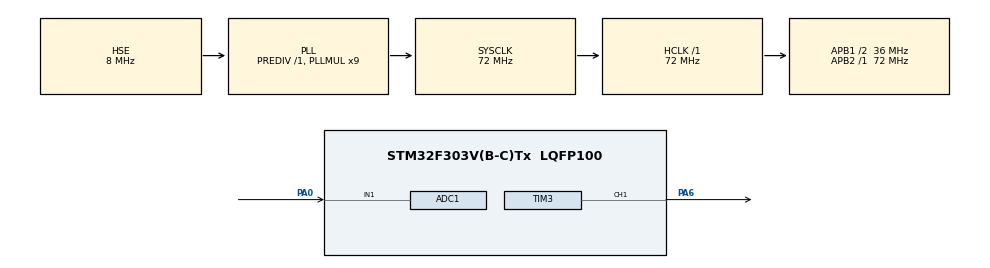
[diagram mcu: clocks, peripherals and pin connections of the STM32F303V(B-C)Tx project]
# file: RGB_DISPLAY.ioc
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ADC1.Channel-0\#ChannelRegularConversion=ADC_CHANNEL_1
ADC1.ContinuousConvMode=DISABLE
ADC1.DMAContinuousRequests=ENABLE
ADC1.EOCSelection=ADC_EOC_SINGLE_CONV
ADC1.EnableInjectedConversion=DISABLE
ADC1.ExternalTrigConv=ADC_EXTERNALTRIGCONV_T6_TRGO
ADC1.NbrOfConversionFlag=1
ADC1.Offset-0\#ChannelRegularConversion=0
ADC1.OffsetNumber-0\#ChannelRegularConversion=ADC_OFFSET_NONE
ADC1.Rank-0\#ChannelRegularConversion=1
ADC1.SamplingTime-0\#ChannelRegularConversion=ADC_SAMPLETIME_1CYCLE_5
ADC1.master=1
Dma.ADC1.1.Direction=DMA_PERIPH_TO_MEMORY
Dma.ADC1.1.Instance=DMA1_Channel1
Dma.ADC1.1.MemDataAlignment=DMA_MDATAALIGN_HALFWORD
Dma.ADC1.1.MemInc=DMA_MINC_ENABLE
Dma.ADC1.1.Mode=DMA_CIRCULAR
Dma.ADC1.1.PeriphDataAlignment=DMA_PDATAALIGN_HALFWORD
Dma.ADC1.1.PeriphInc=DMA_PINC_DISABLE
Dma.ADC1.1.Priority=DMA_PRIORITY_HIGH
Dma.Request0=TIM3_CH4/UP
Dma.Request1=ADC1
Dma.TIM3_CH4/UP.0.Direction=DMA_MEMORY_TO_PERIPH
Dma.TIM3_CH4/UP.0.Instance=DMA1_Channel3
Dma.TIM3_CH4/UP.0.MemDataAlignment=DMA_MDATAALIGN_HALFWORD
Dma.TIM3_CH4/UP.0.MemInc=DMA_MINC_ENABLE
Dma.TIM3_CH4/UP.0.Mode=DMA_CIRCULAR
Dma.TIM3_CH4/UP.0.PeriphDataAlignment=DMA_PDATAALIGN_HALFWORD
Dma.TIM3_CH4/UP.0.PeriphInc=DMA_PINC_DISABLE
Dma.TIM3_CH4/UP.0.Priority=DMA_PRIORITY_VERY_HIGH
Mcu.Family=STM32F3
Mcu.Name=STM32F303V(B-C)Tx
Mcu.Package=LQFP100
NVIC.DMA1_Channel1_IRQn=true\:0\:0\:false\:false\:true\:false
NVIC.DMA1_Channel3_IRQn=true\:0\:0\:false\:false\:true\:false
NVIC.PriorityGroup=NVIC_PRIORITYGROUP_4
NVIC.TIM7_IRQn=true\:0\:0\:false\:false\:true\:true
PA0.Mode=IN1-Single-Ended
PA0.Signal=ADC1_IN1
PA13.Mode=Serial_Wire
PA13.Signal=SYS_JTMS-SWDIO
PA14.Mode=Serial_Wire
PA14.Signal=SYS_JTCK-SWCLK
PA6.GPIO_Speed=GPIO_SPEED_FREQ_LOW
PA6.Signal=S_TIM3_CH1
PC14-OSC32_IN.Mode=LSE-External-Oscillator
PC14-OSC32_IN.Signal=RCC_OSC32_IN
PC15-OSC32_OUT.Mode=LSE-External-Oscillator
PC15-OSC32_OUT.Signal=RCC_OSC32_OUT
PF0-OSC_IN.Mode=HSE-External-Oscillator
PF0-OSC_IN.Signal=RCC_OSC_IN
PF1-OSC_OUT.Mode=HSE-External-Oscillator
PF1-OSC_OUT.Signal=RCC_OSC_OUT
ProjectManager.HeapSize=0x200
ProjectManager.StackSize=0x400
ProjectManager.TargetToolchain=Makefile
RCC.AHBFreq_Value=72000000
RCC.APB1CLKDivider=RCC_HCLK_DIV2
RCC.APB1Freq_Value=36000000
RCC.APB1TimFreq_Value=72000000
RCC.APB2Freq_Value=72000000
RCC.APB2TimFreq_Value=72000000
RCC.CortexFreq_Value=72000000
RCC.HCLKFreq_Value=72000000
RCC.HSE_VALUE=8000000
RCC.HSI_VALUE=8000000
RCC.PLLMUL=RCC_PLL_MUL9
RCC.PLLSourceVirtual=RCC_PLLSOURCE_HSE
RCC.SYSCLKFreq_VALUE=72000000
RCC.SYSCLKSourceVirtual=RCC_SYSCLKSOURCE_PLLCLK
RCC.USBFreq_Value=72000000
SH.S_TIM3_CH1.0=TIM3_CH1,PWM Generation1 CH1
TIM3.AutoReloadPreload=TIM_AUTORELOAD_PRELOAD_ENABLE
TIM3.Channel-PWM\ Generation1\ CH1=TIM_CHANNEL_1
TIM3.OCMode_PWM-PWM\ Generation1\ CH1=TIM_OCMODE_PWM1
TIM3.Period=12
TIM3.Prescaler=6
TIM3.Pulse-PWM\ Generation1\ CH1=0
TIM3.TIM_MasterOutputTrigger=TIM_TRGO_UPDATE
TIM6.AutoReloadPreload=TIM_AUTORELOAD_PRELOAD_ENABLE
TIM6.Period=49
TIM6.Prescaler=72
TIM6.TIM_MasterOutputTrigger=TIM_TRGO_UPDATE
TIM7.AutoReloadPreload=TIM_AUTORELOAD_PRELOAD_ENABLE
TIM7.Period=9999
TIM7.Prescaler=72
TIM7.TIM_MasterOutputTrigger=TIM_TRGO_RESET
VP_TIM3_VS_ClockSourceINT.Mode=Internal
VP_TIM6_VS_ClockSourceINT.Mode=Enable_Timer
VP_TIM7_VS_ClockSourceINT.Mode=Enable_Timer
board=custom

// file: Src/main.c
/* USER CODE BEGIN Header */
/**
  ******************************************************************************
  * @file           : main.c
  * @brief          : Main program body
  ******************************************************************************
  ** This notice applies to any and all portions of this file
  * that are not between comment pairs USER CODE BEGIN and
  * USER CODE END. Other portions of this file, whether
  * inserted by the user or by software development tools
  * are owned by their respective copyright owners.
  *
  * COPYRIGHT(c) 2019 STMicroelectronics
  *
  * Redistribution and use in source and binary forms, with or without modification,
  * are permitted provided that the following conditions are met:
  *   1. Redistributions of source code must retain the above copyright notice,
  *      this list of conditions and the following disclaimer.
  *   2. Redistributions in binary form must reproduce the above copyright notice,
  *      this list of conditions and the following disclaimer in the documentation
  *      and/or other materials provided with the distribution.
  *   3. Neither the name of STMicroelectronics nor the names of its contributors
  *      may be used to endorse or promote products derived from this software
  *      without specific prior written permission.
  *
  * THIS SOFTWARE IS PROVIDED BY THE COPYRIGHT HOLDERS AND CONTRIBUTORS "AS IS"
  * AND ANY EXPRESS OR IMPLIED WARRANTIES, INCLUDING, BUT NOT LIMITED TO, THE
  * IMPLIED WARRANTIES OF MERCHANTABILITY AND FITNESS FOR A PARTICULAR PURPOSE ARE
  * DISCLAIMED. IN NO EVENT SHALL THE COPYRIGHT HOLDER OR CONTRIBUTORS BE LIABLE
  * FOR ANY DIRECT, INDIRECT, INCIDENTAL, SPECIAL, EXEMPLARY, OR CONSEQUENTIAL
  * DAMAGES (INCLUDING, BUT NOT LIMITED TO, PROCUREMENT OF SUBSTITUTE GOODS OR
  * SERVICES; LOSS OF USE, DATA, OR PROFITS; OR BUSINESS INTERRUPTION) HOWEVER
  * CAUSED AND ON ANY THEORY OF LIABILITY, WHETHER IN CONTRACT, STRICT LIABILITY,
  * OR TORT (INCLUDING NEGLIGENCE OR OTHERWISE) ARISING IN ANY WAY OUT OF THE USE
  * OF THIS SOFTWARE, EVEN IF ADVISED OF THE POSSIBILITY OF SUCH DAMAGE.
  *
  ******************************************************************************
  */
/* USER CODE END Header */

#include "main.h"
#include "adc.h"
#include "dma.h"
#include "tim.h"
#include "gpio.h"

void SystemClock_Config(void);
/* USER CODE BEGIN PFP */
void Setup();
void Loop();
/* USER CODE END PFP */

int main(void)
{

  /* MCU Configuration--------------------------------------------------------*/

  /* Reset of all peripherals, Initializes the Flash interface and the Systick. */
  HAL_Init();

  /* Configure the system clock */
  SystemClock_Config();

  /* Initialize all configured peripherals */
  MX_GPIO_Init();
  MX_DMA_Init();
  MX_TIM3_Init();
  MX_TIM6_Init();
  MX_ADC1_Init();
  MX_TIM7_Init();
  /* USER CODE BEGIN 2 */

  Setup();

  /* USER CODE END 2 */

  /* Infinite loop */
  /* USER CODE BEGIN WHILE */
  while (1)
  {
    Loop();
    /* USER CODE END WHILE */

  }
}

void SystemClock_Config(void)
{
  RCC_OscInitTypeDef RCC_OscInitStruct = {0};
  RCC_ClkInitTypeDef RCC_ClkInitStruct = {0};
  RCC_PeriphCLKInitTypeDef PeriphClkInit = {0};

  /**Initializes the CPU, AHB and APB busses clocks
  */
  RCC_OscInitStruct.OscillatorType = RCC_OSCILLATORTYPE_HSE;
  RCC_OscInitStruct.HSEState = RCC_HSE_ON;
  RCC_OscInitStruct.HSEPredivValue = RCC_HSE_PREDIV_DIV1;
  RCC_OscInitStruct.HSIState = RCC_HSI_ON;
  RCC_OscInitStruct.PLL.PLLState = RCC_PLL_ON;
  RCC_OscInitStruct.PLL.PLLSource = RCC_PLLSOURCE_HSE;
  RCC_OscInitStruct.PLL.PLLMUL = RCC_PLL_MUL9;
  if (HAL_RCC_OscConfig(&RCC_OscInitStruct) != HAL_OK)
  {
    Error_Handler();
  }
  /**Initializes the CPU, AHB and APB busses clocks
  */
  RCC_ClkInitStruct.ClockType = RCC_CLOCKTYPE_HCLK|RCC_CLOCKTYPE_SYSCLK
                              |RCC_CLOCKTYPE_PCLK1|RCC_CLOCKTYPE_PCLK2;
  RCC_ClkInitStruct.SYSCLKSource = RCC_SYSCLKSOURCE_PLLCLK;
  RCC_ClkInitStruct.AHBCLKDivider = RCC_SYSCLK_DIV1;
  RCC_ClkInitStruct.APB1CLKDivider = RCC_HCLK_DIV2;
  RCC_ClkInitStruct.APB2CLKDivider = RCC_HCLK_DIV1;

  if (HAL_RCC_ClockConfig(&RCC_ClkInitStruct, FLASH_LATENCY_2) != HAL_OK)
  {
    Error_Handler();
  }
  PeriphClkInit.PeriphClockSelection = RCC_PERIPHCLK_ADC12;
  PeriphClkInit.Adc12ClockSelection = RCC_ADC12PLLCLK_DIV1;
  if (HAL_RCCEx_PeriphCLKConfig(&PeriphClkInit) != HAL_OK)
  {
    Error_Handler();
  }
}

void Error_Handler(void)
{
}

/************************ (C) COPYRIGHT STMicroelectronics *****END OF FILE****/
